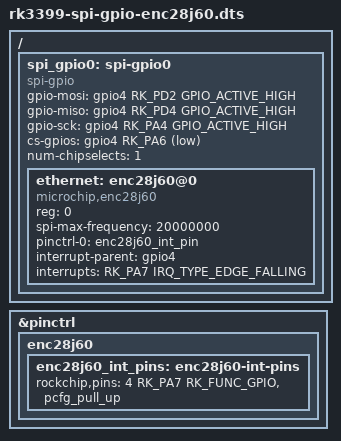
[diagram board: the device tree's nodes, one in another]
/dts-v1/;
/plugin/;

#include <dt-bindings/gpio/gpio.h>
#include <dt-bindings/pinctrl/rockchip.h>
#include <dt-bindings/interrupt-controller/irq.h>

/ {
	fragment@0 {
		target-path = "/";
		__overlay__ {
			spi_gpio0: spi-gpio0 {
				compatible = "spi-gpio";
				#address-cells = <1>;
				#size-cells = <0>;
				ranges;
				gpio-mosi = <&gpio4 RK_PD2 GPIO_ACTIVE_HIGH>;
				gpio-miso = <&gpio4 RK_PD4 GPIO_ACTIVE_HIGH>;
				gpio-sck = <&gpio4 RK_PA4 GPIO_ACTIVE_HIGH>;
				cs-gpios = <&gpio4 RK_PA6 GPIO_ACTIVE_LOW>;
				num-chipselects = <1>;
				status = "okay";

				ethernet: enc28j60@0 {
                    compatible = "microchip,enc28j60";
                    reg = <0>;
                    spi-max-frequency = <20000000>;

                    pinctrl-names = "default";
                    pinctrl-0 = <&enc28j60_int_pin>;

                    interrupt-parent = <&gpio4>;
                    interrupts = <RK_PA7 IRQ_TYPE_EDGE_FALLING>;
				};
			};
		};
	};

	fragment@1 {
		target = <&pinctrl>;
		__overlay__ {
			enc28j60 {
				enc28j60_int_pins: enc28j60-int-pins {
					rockchip,pins = <4 RK_PA7 RK_FUNC_GPIO &pcfg_pull_up>;
				};
			};
		};
	};
};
